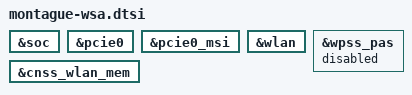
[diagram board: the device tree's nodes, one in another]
#include "ravelin-idp.dtsi"

&soc {
};

&pcie0 {
	status = "ok";
};

&pcie0_msi {
	status = "ok";
};

&wlan {
	status = "ok";
};

&cnss_wlan_mem {
	status = "ok";
};

&wpss_pas {
	status = "disabled";
};
